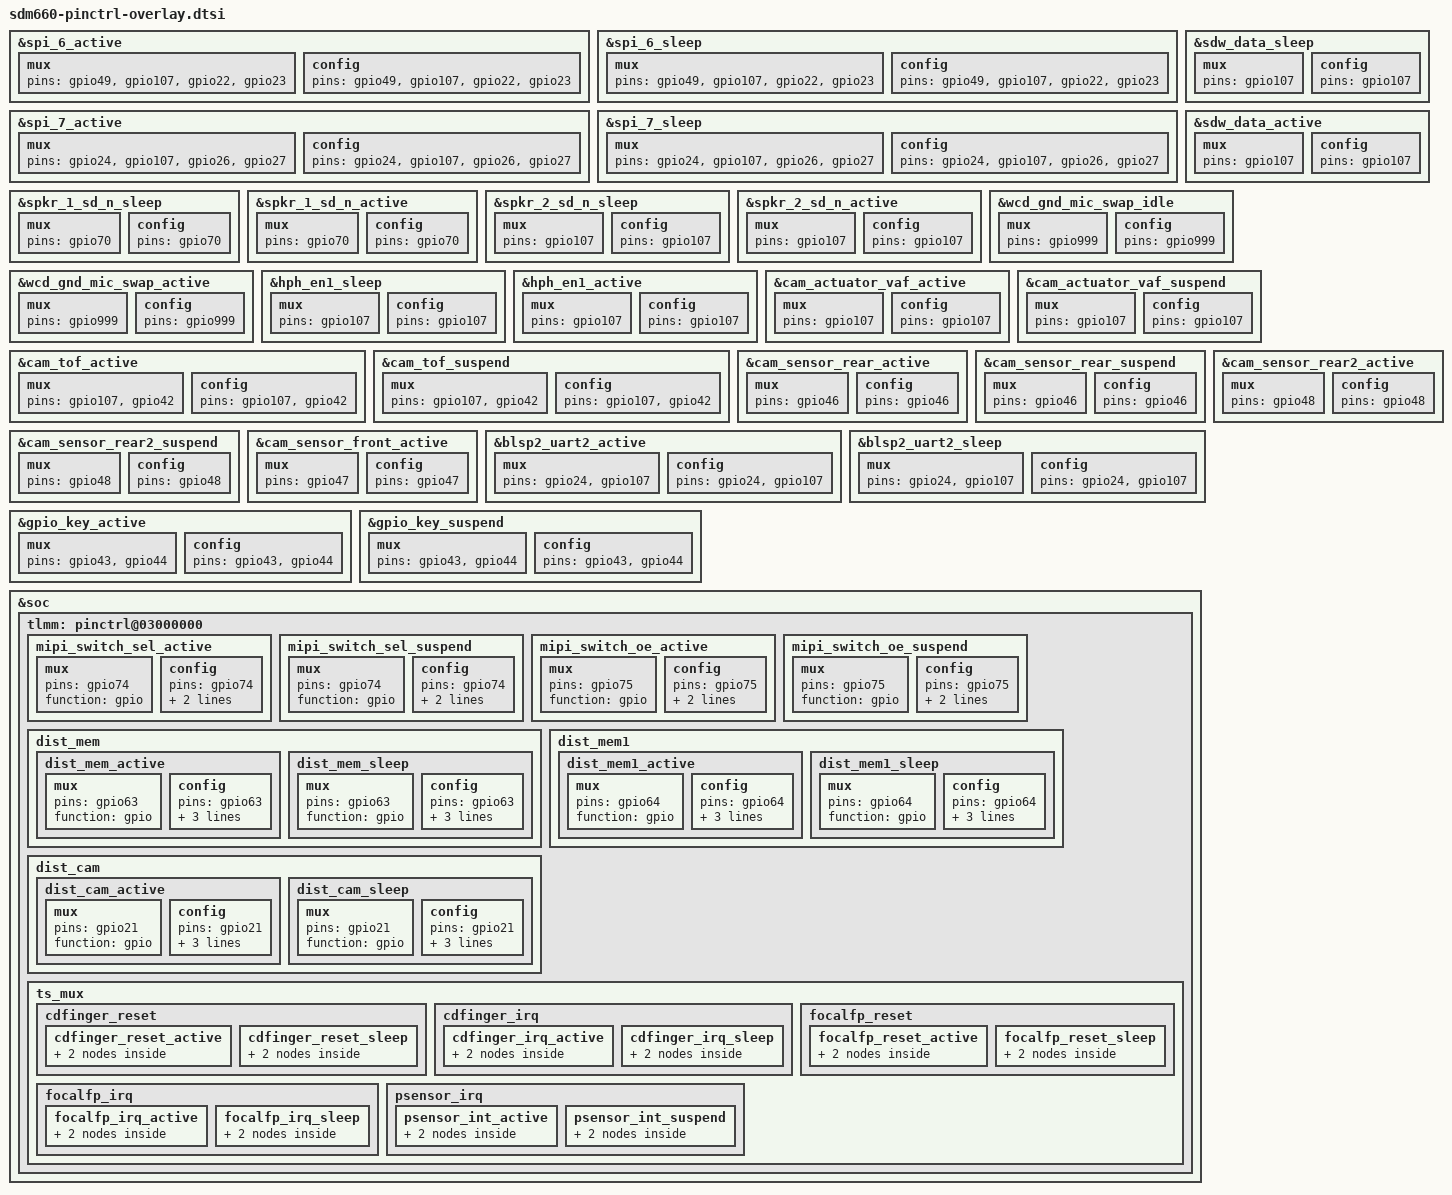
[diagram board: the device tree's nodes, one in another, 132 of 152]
/* SPDX-License-Identifier: GPL-2.0 */
&spi_6_active {
	mux {
		pins = "gpio49", "gpio107",
				"gpio22", "gpio23";
	};

	config {
		pins = "gpio49", "gpio107",
				"gpio22", "gpio23";
	};
};

&spi_6_sleep {
	mux {
		pins = "gpio49", "gpio107",
				"gpio22", "gpio23";
	};

	config {
		pins = "gpio49", "gpio107",
				"gpio22", "gpio23";
	};
};

&spi_7_active {
	mux {
		pins = "gpio24", "gpio107",
				"gpio26", "gpio27";
	};

	config {
		pins = "gpio24", "gpio107",
				"gpio26", "gpio27";
	};
};

&spi_7_sleep {
	mux {
		pins = "gpio24", "gpio107",
				"gpio26", "gpio27";
	};

	config {
		pins = "gpio24", "gpio107",
				"gpio26", "gpio27";
	};
};

&sdw_data_sleep {
	mux {
		pins = "gpio107";
	};

	config {
		pins = "gpio107";
	};
};

&sdw_data_active {
	mux {
		pins = "gpio107";
	};

	config {
		pins = "gpio107";
	};
};

&spkr_1_sd_n_sleep {
	mux {
		pins = "gpio70";
	};

	config {
		pins = "gpio70";
	};
};

&spkr_1_sd_n_active {
	mux {
		pins = "gpio70";
	};

	config {
		pins = "gpio70";
	};
};

&spkr_2_sd_n_sleep {
	mux {
		pins = "gpio107";
	};

	config {
		pins = "gpio107";
	};
};

&spkr_2_sd_n_active {
	mux {
		pins = "gpio107";
	};

	config {
		pins = "gpio107";
	};
};

&wcd_gnd_mic_swap_idle {
	mux {
		pins = "gpio999";
	};

	config {
		pins = "gpio999";
	};
};

&wcd_gnd_mic_swap_active {
	mux {
		pins = "gpio999";
	};

	config {
		pins = "gpio999";
	};
};

&hph_en1_sleep {
	mux {
		pins = "gpio107";
	};

	config {
		pins = "gpio107";
	};
};

&hph_en1_active {
	mux {
		pins = "gpio107";
	};

	config {
		pins = "gpio107";
	};
};

&cam_actuator_vaf_active {
	mux {
		pins = "gpio107";
	};

	config {
		pins = "gpio107";
	};
};

&cam_actuator_vaf_suspend {
	mux {
		pins = "gpio107";
	};

	config {
		pins = "gpio107";
	};
};

&cam_tof_active {
	mux {
		pins = "gpio107", "gpio42";
	};

	config {
		pins = "gpio107", "gpio42";
	};
};

&cam_tof_suspend {
	mux {
		pins = "gpio107", "gpio42";
	};

	config {
		pins = "gpio107", "gpio42";
	};
};

&cam_sensor_rear_active {
	mux {
		pins = "gpio46";
	};

	config {
		pins = "gpio46";
	};
};

&cam_sensor_rear_suspend {
	mux {
		pins = "gpio46";
	};

	config {
		pins = "gpio46";
	};
};

&cam_sensor_rear2_active {
	/* RESET */
	mux {
		pins = "gpio48";
	};

	config {
		pins = "gpio48";
	};
};

&cam_sensor_rear2_suspend {
	/* RESET */
	mux {
		pins = "gpio48";
	};

	config {
		pins = "gpio48";
	};
};

&cam_sensor_front_active {
	mux {
		pins = "gpio47";
	};

	config {
		pins = "gpio47";
	};
};

&blsp2_uart2_active {
	mux {
		pins = "gpio24", "gpio107";
	};

	config {
		pins = "gpio24", "gpio107";
	};
};

&blsp2_uart2_sleep {
	mux {
		pins = "gpio24", "gpio107";
	};

	config {
		pins = "gpio24", "gpio107";
	};
};

&gpio_key_active {
	mux {
		pins = "gpio43", "gpio44";
	};

	config {
		pins = "gpio43", "gpio44";
	};
};

&gpio_key_suspend {
	mux {
		pins = "gpio43", "gpio44";
	};

	config {
		pins = "gpio43", "gpio44";
	};
};

&soc {
	tlmm: pinctrl@03000000 {
		mipi_switch_sel_active: mipi_switch_sel_active {
			/* RESET */
			mux {
				pins = "gpio74";
				function = "gpio";
			};

			config {
				pins = "gpio74";
				bias-disable; /* No PULL */
				drive-strength = <2>; /* 2 MA */
			};
		};

		mipi_switch_sel_suspend: mipi_switch_sel_suspend {
			/* RESET */
			mux {
				pins = "gpio74";
				function = "gpio";
			};

			config {
				pins = "gpio74";
				bias-disable; /* No PULL */
				drive-strength = <2>; /* 2 MA */
			};
		};

		mipi_switch_oe_active: mipi_switch_oe_active {
			/* RESET */
			mux {
				pins = "gpio75";
				function = "gpio";
			};

			config {
				pins = "gpio75";
				bias-disable; /* No PULL */
				drive-strength = <2>; /* 2 MA */
			};
		};

		mipi_switch_oe_suspend: mipi_switch_oe_suspend {
			/* RESET */
			mux {
				pins = "gpio75";
				function = "gpio";
			};

			config {
				pins = "gpio75";
				bias-disable; /* No PULL */
				drive-strength = <2>; /* 2 MA */
			};
		};

		dist_mem {
			dist_mem_active: dist_mem_active {
				mux {
					pins = "gpio63";
					function = "gpio";
				};

				config {
					pins = "gpio63";
					drive-strength = <2>;
					bias-pull-up;
					input-enable;
				};
			};

			dist_mem_sleep: dist_mem_sleep {
				mux {
					pins = "gpio63";
					function = "gpio";
				};

				config {
					pins = "gpio63";
					drive-strength = <2>;
					bias-pull-up;
					input-enable;
				};
			};
		};

		dist_mem1 {
			dist_mem1_active: dist_mem1_active {
				mux {
					pins = "gpio64";
					function = "gpio";
				};

				config {
					pins = "gpio64";
					drive-strength = <2>;
					bias-pull-up;
					input-enable;
				};
			};

			dist_mem1_sleep: dist_mem1_sleep {
				mux {
					pins = "gpio64";
					function = "gpio";
				};

				config {
					pins = "gpio64";
					drive-strength = <2>;
					bias-pull-up;
					input-enable;
				};
			};
		};

		dist_cam {
			dist_cam_active: dist_cam_active {
				mux {
					pins = "gpio21";
					function = "gpio";
				};

				config {
					pins = "gpio21";
					drive-strength = <2>;
					bias-pull-up;
					input-enable;
				};
			};

			dist_cam_sleep: dist_cam_sleep {
				mux {
					pins = "gpio21";
					function = "gpio";
				};

				config {
					pins = "gpio21";
					drive-strength = <2>;
					bias-pull-up;
					input-enable;
				};
			};
		};

		ts_mux {
			cdfinger_reset {
				cdfinger_reset_active: cdfinger_reset_active {
					mux {
						pins = "gpio20";
						function = "gpio";
					};

					config {
						pins = "gpio20";
						drive-strength = <2>;
						bias-pull-up;
					};
				};

				cdfinger_reset_sleep: cdfinger_reset_sleep {
					mux {
						pins = "gpio20";
						function = "gpio";
					};

					config {
						pins = "gpio20";
						drive-strength = <2>;
						bias-pull-up;
					};
				};
			};

			cdfinger_irq {
				cdfinger_irq_active: cdfinger_irq_active {
					mux {
						pins = "gpio72";
						function = "gpio";
					};

					config {
						pins = "gpio72";
						drive-strength = <2>;
						bias-disable;
					};
				};

				cdfinger_irq_sleep: cdfinger_irq_sleep {
					mux {
						pins = "gpio72";
						function = "gpio";
					};

					config {
						pins = "gpio72";
						drive-strength = <2>;
						bias-disable;
					};
				};
			};

			focalfp_reset {
				focalfp_reset_active: focalfp_reset_active {
					mux {
						pins = "gpio20";
						function = "gpio";
					};

					config {
						pins = "gpio20";
						drive-strength = <2>;
						bias-pull-up;
					};
				};

				focalfp_reset_sleep: focalfp_reset_sleep {
					mux {
						pins = "gpio20";
						function = "gpio";
					};

					config {
						pins = "gpio20";
						drive-strength = <2>;
						bias-pull-up;
					};
				};
			};

			focalfp_irq {
				focalfp_irq_active: focalfp_irq_active {
					mux {
						pins = "gpio72";
						function = "gpio";
					};

					config {
						pins = "gpio72";
						drive-strength = <2>;
						bias-disable;
					};
				};

				focalfp_irq_sleep: focalfp_irq_sleep {
					mux {
						pins = "gpio72";
						function = "gpio";
					};

					config {
						pins = "gpio72";
						drive-strength = <2>;
						bias-disable;
					};
				};
			};

			psensor_irq {
				psensor_int_active: psensor_int_active {
					mux {
						pins = "gpio45";
						function = "gpio";
					};

					config {
						pins = "gpio45";
						drive-strength = <2>;
						bias-pull-up;
						input-enable;
					};
				};

				psensor_int_suspend: psensor_int_suspend {
					mux {
						pins = "gpio45";
						function = "gpio";
					};

					config {
						pins = "gpio45";
						drive-strength = <2>;
						bias-pull-up;
						input-enable;
					};
				};
			};
		};
	};
};
